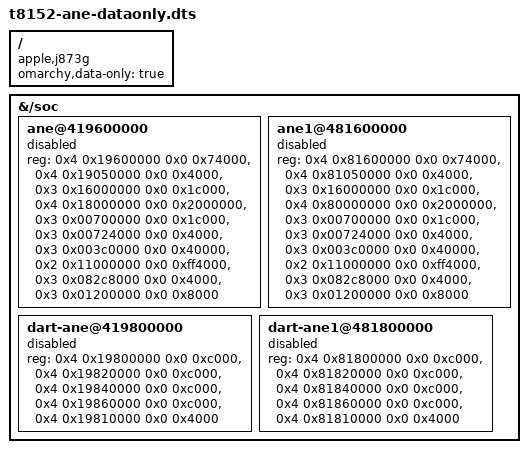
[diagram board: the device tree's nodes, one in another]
// SPDX-License-Identifier: GPL-2.0+ OR MIT
/*
 * Static ANE data for T8152 (j873g, Apple Mac mini M6), from the macOS 27.0
 * IPSW DeviceTree.j873gap.adt. Data-only: no driver binds this; runtime must
 * refuse to apply it, even if an opt-in key exists. Nodes are disabled and
 * have no ANE compatible or phandles. IRQ values remain in the JSON because
 * the checked target does not export an AIC symbol for this overlay.
 */
/dts-v1/;
/plugin/;

/ {
	omarchy,data-only = "true";
	compatible = "apple,j873g";

	fragment@0 {
		target-path = "/soc";
		__overlay__ {
			#address-cells = <2>;
			#size-cells = <2>;
			ane@419600000 {
				reg = <0x4 0x19600000 0x0 0x74000>,
				      <0x4 0x19050000 0x0 0x4000>,
				      <0x3 0x16000000 0x0 0x1c000>,
				      <0x4 0x18000000 0x0 0x2000000>,
				      <0x3 0x00700000 0x0 0x1c000>,
				      <0x3 0x00724000 0x0 0x4000>,
				      <0x3 0x003c0000 0x0 0x40000>,
				      <0x2 0x11000000 0x0 0xff4000>,
				      <0x3 0x082c8000 0x0 0x4000>,
				      <0x3 0x01200000 0x0 0x8000>;
				status = "disabled";
			};

			ane1@481600000 {
				reg = <0x4 0x81600000 0x0 0x74000>,
				      <0x4 0x81050000 0x0 0x4000>,
				      <0x3 0x16000000 0x0 0x1c000>,
				      <0x4 0x80000000 0x0 0x2000000>,
				      <0x3 0x00700000 0x0 0x1c000>,
				      <0x3 0x00724000 0x0 0x4000>,
				      <0x3 0x003c0000 0x0 0x40000>,
				      <0x2 0x11000000 0x0 0xff4000>,
				      <0x3 0x082c8000 0x0 0x4000>,
				      <0x3 0x01200000 0x0 0x8000>;
				status = "disabled";
			};

			dart-ane@419800000 {
				reg = <0x4 0x19800000 0x0 0xc000>,
				      <0x4 0x19820000 0x0 0xc000>,
				      <0x4 0x19840000 0x0 0xc000>,
				      <0x4 0x19860000 0x0 0xc000>,
				      <0x4 0x19810000 0x0 0x4000>;
				status = "disabled";
			};

			dart-ane1@481800000 {
				reg = <0x4 0x81800000 0x0 0xc000>,
				      <0x4 0x81820000 0x0 0xc000>,
				      <0x4 0x81840000 0x0 0xc000>,
				      <0x4 0x81860000 0x0 0xc000>,
				      <0x4 0x81810000 0x0 0x4000>;
				status = "disabled";
			};
		};
	};
};
